# ATtiny88 device description
Architecture: AVR8; Family: tinyAVR
Registers are 8-bit, access not given, no defined reset value unless marked. A register's access mark holds for its fields unless they carry their own. Offsets are from the block's base; [hi:lo] are bit positions.

## FUSE — Fuses
Instances: FUSE 0 in fuses
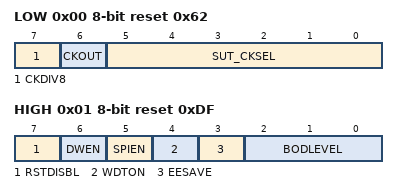
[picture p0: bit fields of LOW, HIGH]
0x00 LOW reset 0x62
  [7] CKDIV8 — Divide clock by 8 internally
  [6] CKOUT — Clock output on PORTB0
  [5:0] SUT_CKSEL — Select Clock Source
    12=EXTCLK_6CK_14CK_0MS (Ext. Clock; Start-up time PWRDWN/RESET: 6 CK/14 CK + 0 ms); 28=EXTCLK_6CK_14CK_4MS1 (Ext. Clock; Start-up time PWRDWN/RESET: 6 CK/14 CK + 4.1 ms); 44=EXTCLK_6CK_14CK_65MS (Ext. Clock; Start-up time PWRDWN/RESET: 6 CK/14 CK + 65 ms); 14=INTRCOSC_8MHZ_6CK_14CK_0MS (Int. RC Osc. 8 MHz; Start-up time PWRDWN/RESET: 6 CK/14 CK + 0 ms); 30=INTRCOSC_8MHZ_6CK_14CK_4MS1 (Int. RC Osc. 8 MHz; Start-up time PWRDWN/RESET: 6 CK/14 CK + 4.1 ms); 46=INTRCOSC_8MHZ_6CK_14CK_65MS_DEFAULT (Int. RC Osc. 8 MHz; Start-up time PWRDWN/RESET: 6 CK/14 CK + 65 ms; default value); 15=INTRCOSC_128KHZ_6CK_14CK_0MS (Int. RC Osc. 128kHz; Start-up time PWRDWN/RESET: 6 CK/14 CK + 0 ms); 31=INTRCOSC_128KHZ_6CK_14CK_4MS1 (Int. RC Osc. 128kHz; Start-up time PWRDWN/RESET: 6 CK/14 CK + 4.1 ms); 47=INTRCOSC_128KHZ_6CK_14CK_65MS (Int. RC Osc. 128kHz; Start-up time PWRDWN/RESET: 6 CK/14 CK + 65 ms)
0x01 HIGH reset 0xDF
  [7] RSTDISBL — Reset Disabled (Enable PC6 as i/o pin)
  [6] DWEN — Debug Wire enable
  [5] SPIEN — Serial program downloading (SPI) enabled
  [4] WDTON — Watch-dog Timer always on
  [3] EESAVE — Preserve EEPROM through the Chip Erase cycle
  [2:0] BODLEVEL — Brown-out Detector trigger level
    4=4V3 (Brown-out detection at VCC=4.3 V); 5=2V7 (Brown-out detection at VCC=2.7 V); 6=1V8 (Brown-out detection at VCC=1.8 V); 7=DISABLED (Brown-out detection disabled)
0x02 EXTENDED reset 0xFF
  [0] SELFPRGEN — Self Programming enable

## LOCKBIT — Lockbits
Instances: LOCKBIT 0 in lockbits
0x00 LOCKBIT reset 0xFF
  [1:0] LB — Memory Lock
    0=PROG_VER_DISABLED (Further programming and verification disabled); 2=PROG_DISABLED (Further programming disabled); 3=NO_LOCK (No memory lock features enabled)

## TC1 (TC16 module) — Timer/Counter, 16-bit
Instances: TC1 0x00
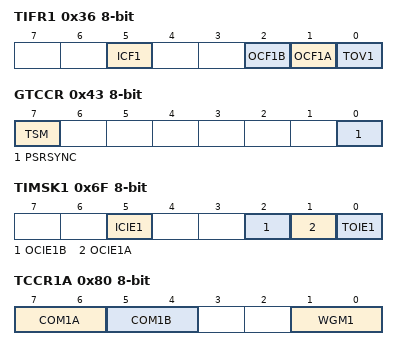
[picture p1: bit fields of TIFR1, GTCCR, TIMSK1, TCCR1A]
0x36 TIFR1 — Timer/Counter Interrupt Flag register
  [5] ICF1 — Input Capture Flag 1
  [2] OCF1B — Output Compare Flag 1B
  [1] OCF1A — Output Compare Flag 1A
  [0] TOV1 — Timer/Counter1 Overflow Flag
0x43 GTCCR — General Timer/Counter Control Register
  [7] TSM — Timer/Counter Synchronization Mode
  [0] PSRSYNC — Prescaler Reset Timer/Counter1 and Timer/Counter0
0x6F TIMSK1 — Timer/Counter Interrupt Mask Register
  [5] ICIE1 — Timer/Counter1 Input Capture Interrupt Enable
  [2] OCIE1B — Timer/Counter1 Output CompareB Match Interrupt Enable
  [1] OCIE1A — Timer/Counter1 Output CompareA Match Interrupt Enable
  [0] TOIE1 — Timer/Counter1 Overflow Interrupt Enable
0x80 TCCR1A — Timer/Counter1 Control Register A
  [7:6] COM1A — Compare Output Mode 1A, bits
  [5:4] COM1B — Compare Output Mode 1B, bits
  [1:0] WGM1 — Waveform Generation Mode
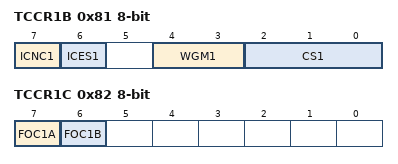
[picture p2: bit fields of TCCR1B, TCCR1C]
0x81 TCCR1B — Timer/Counter1 Control Register B
  [7] ICNC1 — Input Capture 1 Noise Canceler
  [6] ICES1 — Input Capture 1 Edge Select
  [4:3] WGM1 (bit 2 of the value upward) — Waveform Generation Mode
  [2:0] CS1 — Prescaler source of Timer/Counter 1
    0=NO_CLOCK_SOURCE_STOPPED; 1=RUNNING_NO_PRESCALING; 2=RUNNING_CLK_8; 3=RUNNING_CLK_64; 4=RUNNING_CLK_256; 5=RUNNING_CLK_1024; 6=RUNNING_EXTCLK_TN_FALLING_EDGE; 7=RUNNING_EXTCLK_TN_RISING_EDGE
0x82 TCCR1C — Timer/Counter1 Control Register C
  [7] FOC1A, [6] FOC1B
0x84 TCNT1 16-bit — Timer/Counter1 Bytes
0x86 ICR1 16-bit — Timer/Counter1 Input Capture Register Bytes
0x88 OCR1A 16-bit — Timer/Counter1 Output Compare Register Bytes
0x8A OCR1B 16-bit — Timer/Counter1 Output Compare Register Bytes

## AC — Analog Comparator
Instances: AC 0x00
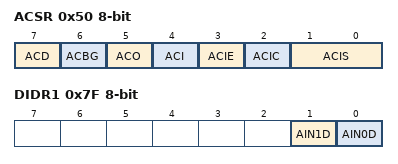
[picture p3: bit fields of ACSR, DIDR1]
0x50 ACSR — Analog Comparator Control And Status Register
  [7] ACD — Analog Comparator Disable
  [6] ACBG — Analog Comparator Bandgap Select
  [5] ACO — Analog Compare Output
  [4] ACI — Analog Comparator Interrupt Flag
  [3] ACIE — Analog Comparator Interrupt Enable
  [2] ACIC — Analog Comparator Input Capture Enable
  [1:0] ACIS — Analog Comparator Interrupt Mode Select bits
    0=INTERRUPT_ON_TOGGLE; 2=INTERRUPT_ON_FALLING_EDGE; 3=INTERRUPT_ON_RISING_EDGE
0x7F DIDR1 — Digital Input Disable Register 1
  [1] AIN1D — AIN1 Digital Input Disable
  [0] AIN0D — AIN0 Digital Input Disable
